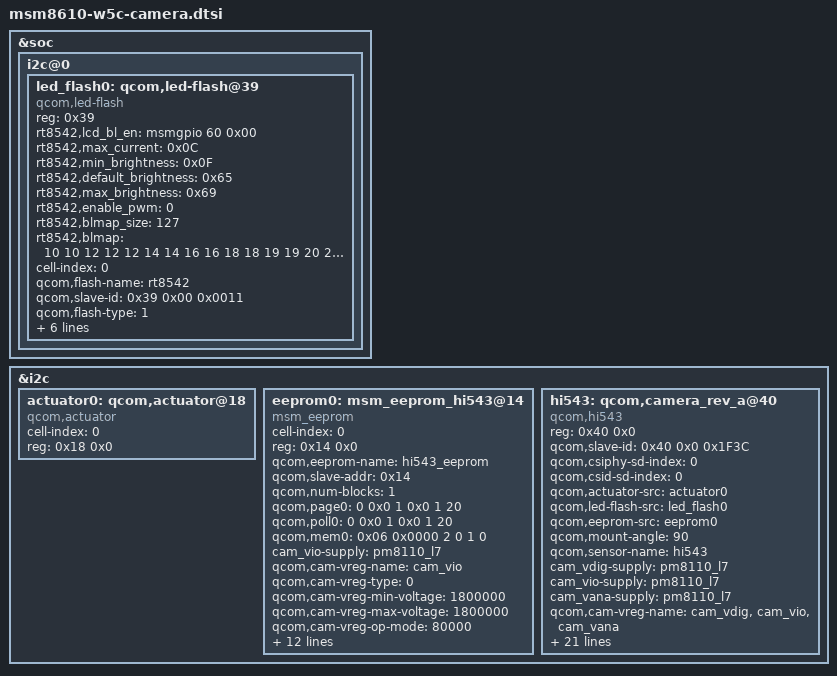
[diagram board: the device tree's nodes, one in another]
/*
 * Copyright (c) 2013, The Linux Foundation. All rights reserved.
 *
 * This program is free software; you can redistribute it and/or modify
 * it under the terms of the GNU General Public License version 2 and
 * only version 2 as published by the Free Software Foundation.
 *
 * This program is distributed in the hope that it will be useful,
 * but WITHOUT ANY WARRANTY; without even the implied warranty of
 * MERCHANTABILITY or FITNESS FOR A PARTICULAR PURPOSE.  See the
 * GNU General Public License for more details.
 */

&soc {
	i2c@0 {
		led_flash0: qcom,led-flash@39 {
			compatible = "qcom,led-flash";
			status = "ok";
			reg = <0x39>;
			rt8542,lcd_bl_en = <&msmgpio 60 0x00>;
			rt8542,max_current = <0x0C>;
			rt8542,min_brightness = <0x0F>;
			rt8542,default_brightness = <0x65>;
			rt8542,max_brightness = <0x69>;
			rt8542,enable_pwm = <0>;
			rt8542,blmap_size = <127>;
			rt8542,blmap = <
				10 10 12 12 12 14 14 16 16 18
				18 19 19 20 20 22 22 22 24 24
				26 26 28 28 29 29 30 30 32 32
				32 34 34 36 36 38 38 39 39 40
				40 42 42 42 44 44 46 46 48 48
				49 49 50 50 52 52 52 54 54 56
				56 58 58 59 59 60 60 62 62 62
				64 64 66 66 68 68 69 69 70 70
				72 72 72 74 74 76 76 78 78 79
				79 80 80 82 82 82 84 84 86 86
				88 88 89 89 90 90 92 92 92 94
				94 96 96 96 98 98 99 99 100 100
				102 102 104 104 105 105 105>;

			cell-index = <0>;
			qcom,flash-name = "rt8542";
			qcom,slave-id = <0x39 0x00 0x0011>;
			qcom,flash-type = <1>;
			qcom,gpio-no-mux = <0>;
			gpios = <&msmgpio 18 0>;
			qcom,gpio-flash-en = <0>;
			qcom,gpio-req-tbl-num = <0>;
			qcom,gpio-req-tbl-flags = <0>;
			qcom,gpio-req-tbl-label = "FLASH_EN";

		};
	};
};

&i2c {

/* HI543(5M) actuator */
	actuator0: qcom,actuator@18 {
		cell-index = <0>;	//Use Af_main_0 of dw9716 with HI543(5M)
		reg = <0x18 0x0>;
		compatible = "qcom,actuator";
		status = "okay";
	};

/* HI543(5M) eeprom */
	eeprom0: msm_eeprom_hi543@14 { //EEPROM READ
		cell-index = <0>;
		reg = <0x14 0x0>;
		qcom,eeprom-name = "hi543_eeprom";
		compatible = "msm_eeprom";
		qcom,slave-addr = <0x14>;

		qcom,num-blocks = <1>;
		qcom,page0 = <0 0x0 1 0x0 1 20>; // valid size, addr, addr_t, data, data_t, delay
		qcom,poll0 = <0 0x0 1 0x0 1 20>;
		qcom,mem0  = <0x06 0x0000 2 0 1 0>; //EEPROM READ

		cam_vio-supply = <&pm8110_l7>;
		qcom,cam-vreg-name = "cam_vio";
		qcom,cam-vreg-type = <0>;
        	qcom,cam-vreg-min-voltage = <1800000>;
       		qcom,cam-vreg-max-voltage = <1800000>;
		qcom,cam-vreg-op-mode = <80000>;

		qcom,gpio-no-mux = <0>;
		gpios = <&msmgpio 20 0>;		//2.8V VCM
		qcom,gpio-standby = <0>;		//CAM_STANDBY
		qcom,gpio-req-tbl-num = <0>;
		qcom,gpio-req-tbl-flags = <0>;
		qcom,gpio-req-tbl-label = "CAM_STANDBY";

		qcom,cam-power-seq-type = "sensor_vreg","sensor_gpio";
		qcom,cam-power-seq-val = "cam_vio","sensor_gpio_standby";
		qcom,cam-power-seq-cfg-val = <1 1>;
		qcom,cam-power-seq-delay = <1 1>;
	};

/* Rev A ~ */
	hi543: qcom,camera_rev_a@40 {
		compatible = "qcom,hi543";
		reg = <0x40 0x0>;
		qcom,slave-id = <0x40 0x0 0x1F3C>;
		qcom,csiphy-sd-index = <0>;
		qcom,csid-sd-index = <0>;
		qcom,actuator-src = <&actuator0>;
		qcom,led-flash-src = <&led_flash0>;
		qcom,eeprom-src = <&eeprom0>;
		qcom,mount-angle = <90>;
		qcom,sensor-name = "hi543";
		cam_vdig-supply = <&pm8110_l7>;             /* Dummy VDIG Setting, We never use this LDO7 for DIG, youngwook.song@lge.com, 2013.08.26 */
		cam_vio-supply = <&pm8110_l7>;
		cam_vana-supply = <&pm8110_l7>;            /* Dummy VANA Setting, We never use this LDO7 for DIG, youngwook.song@lge.com, 2013.08.26  */
		qcom,cam-vreg-name = "cam_vdig", "cam_vio", "cam_vana";
		qcom,cam-vreg-type = <0 0 0>;
		qcom,cam-vreg-min-voltage = <1300000 1800000 2850000>;
		qcom,cam-vreg-max-voltage = <1300000 1800000 2850000>;
		qcom,cam-vreg-op-mode = <200000 80000 80000>;

		qcom,gpio-no-mux = <0>;
		gpios = <&msmgpio 13 0>,
			<&msmgpio 21 0>,
			<&msmgpio 20 0>,
                        <&msmgpio 85 0>;
		qcom,gpio-reset = <1>;
		qcom,gpio-standby = <2>;
		qcom,gpio-vana = <3>;
		qcom,gpio-req-tbl-num = <0 1 2 3>;
		qcom,gpio-req-tbl-flags = <1 0 0 0>;
		qcom,gpio-req-tbl-label = "CAMIF_MCLK", "CAM_RESET1", "CAM_STANDBY", "MAIN_VANA_EN";
		qcom,csi-lane-assign = <0xe4>;
		qcom,csi-lane-mask = <0x7>;
		qcom,sensor-position = <0>;
		qcom,sensor-mode = <0>;
		status = "okay";
		revision = "rev_a...";
	};
};
